# ESP32-P4 register map
Vendor: ESPRESSIF SYSTEMS (SHANGHAI) CO., LTD.; Series: ESP32 P-Series; File version: 3
CPU: RV32IMAFC r0p0, little endian, no MPU, FPU, 0 interrupt priority bits
Address unit: 32 bits
Registers are 32-bit, read-write, reset 0x0 unless marked. A register's access mark holds for its fields unless they carry their own. Offsets are from the block's base; [hi:lo] are bit positions; {n}, {i} and the like mark numbered series.

## I3C_MST_MEM — I3C_MST_MEM Peripheral
Base 0x500DA000
0x08 COMMAND_BUF_PORT
  [31:0] REG_COMMAND — Contains a Command Descriptor structure that depends on the requested transfer type. Command Descriptor structure is used to schedule the transfers to devices on I3C bus.
0x0C RESPONSE_BUF_PORT ro
  [31:0] RESPONSE — The Response Buffer can be read through this register. The response status for each Command is written into the Response Buffer by the controller if ROC (Response On Completion) bit is set or if transfer error has occurred. The response buffer can be read through this register.
0x10 RX_DATA_PORT ro
  [31:0] RX_DATA_PORT — Receive Data Port. Receive data is mapped to the Rx-data buffer and receive data is always packed in 4-byte aligned data words. If the length of data transfer is not aligned to 4-bytes boundary, then there will be extra(unused) bytes(the additional data bytes have to be ignored) at the end of the transferred data. The valid data must be identified using the DATA_LENGTH filed in the Response Descriptor.
0x14 TX_DATA_PORT
  [31:0] REG_TX_DATA_PORT — Transmit Data Port. Transmit data is mapped to the Tx-data buffer and transmit data is always packed in 4-byte aligned data words. If the length of data transfer is not aligned to 4-bytes boundary, then there will be extra(unused) bytes(the additional data bytes have to be ignored) at the end of the transferred data. The valid data must be identified using the DATA_LENGTH filed in the Response Descriptor.
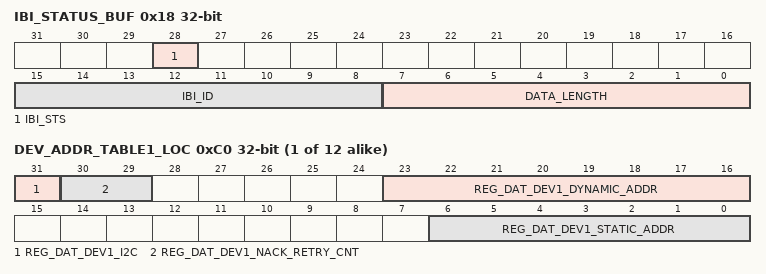
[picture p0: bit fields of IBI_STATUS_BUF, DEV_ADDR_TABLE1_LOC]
0x18 IBI_STATUS_BUF ro — In-Band Interrupt Buffer Status/Data Register. When receiving an IBI, IBI_PORT is used to both: Read the IBI Status Read the IBI Data(which is raw/opaque data)
  [28] IBI_STS — IBI received data/status. IBI Data register is mapped to the IBI Buffer. The IBI Data is always packed in4-byte aligned and put to the IBI Buffer. This register When read from, reads the data from the IBI buffer. IBI Status register when read from, returns the data from the IBI Buffer and indicates how the controller responded to incoming IBI(SIR, MR and HJ).
  [15:8] IBI_ID — IBI Identifier. The byte received after START which includes the address the R/W bit: Device address and R/W bit in case of Slave Interrupt or Master Request.
  [7:0] DATA_LENGTH — This field represents the length of data received along with IBI, in bytes.
0x40 IBI_DATA_BUF ro
  [31:0] IBI_DATA
{0xBC+4i} DEV_ADDR_TABLE{i}_LOC (i=1..12)
  [31] REG_DAT_DEV{i}_I2C — Legacy I2C device or not. This bit should be set to 1 if the device is a legacy I2C device.
  [30:29] REG_DAT_DEV{i}_NACK_RETRY_CNT — This field is used to set the Device NACK Retry count for the particular device. If the Device NACK's for the device address, the controller automatically retries the same device until this count expires. If the Slave does not ACK for the mentioned number of retries, then controller generates an error response and move to the Halt state.
  [23:16] REG_DAT_DEV{i}_DYNAMIC_ADDR — Device Dynamic Address with parity, The MSB,bit[23], should be programmed with parity of dynamic address.
  [6:0] REG_DAT_DEV{i}_STATIC_ADDR
{0xF0+0x10*i} DEV_CHAR_TABLE{i}_LOC1 ro (i=1..12)
  [31:0] DCT_DEV{i}_LOC1
{0xF4+0x10*i} DEV_CHAR_TABLE{i}_LOC2 ro (i=1..12)
  [31:0] DCT_DEV{i}_LOC2
{0xF8+0x10*i} DEV_CHAR_TABLE{i}_LOC3 ro (i=1..12)
  [31:0] DCT_DEV{i}_LOC3
{0xFC+0x10*i} DEV_CHAR_TABLE{i}_LOC4 ro (i=1..12)
  [31:0] DCT_DEV{i}_LOC4

## AXI_ICM — AXI_ICM Peripheral
Base 0x500A4000
0x00 VERID_FILEDS ro reset 0x3430342A
  [31:0] ICM_REG_VERID
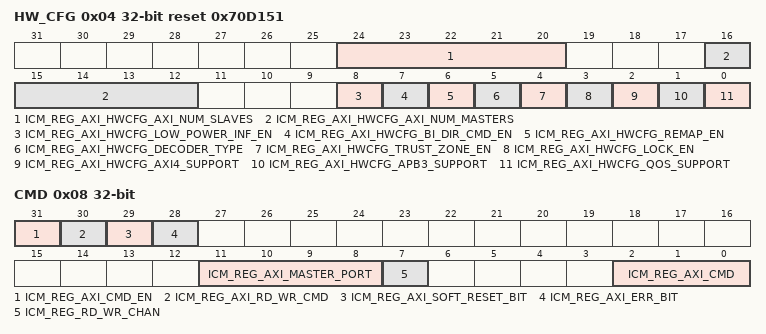
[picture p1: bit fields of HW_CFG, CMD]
0x04 HW_CFG ro reset 0x70D151
  [24:20] ICM_REG_AXI_HWCFG_AXI_NUM_SLAVES, [16:12] ICM_REG_AXI_HWCFG_AXI_NUM_MASTERS, [8] ICM_REG_AXI_HWCFG_LOW_POWER_INF_EN, [7] ICM_REG_AXI_HWCFG_BI_DIR_CMD_EN, [6] ICM_REG_AXI_HWCFG_REMAP_EN, [5] ICM_REG_AXI_HWCFG_DECODER_TYPE, [4] ICM_REG_AXI_HWCFG_TRUST_ZONE_EN, [3] ICM_REG_AXI_HWCFG_LOCK_EN, [2] ICM_REG_AXI_HWCFG_AXI4_SUPPORT, [1] ICM_REG_AXI_HWCFG_APB3_SUPPORT, [0] ICM_REG_AXI_HWCFG_QOS_SUPPORT
0x08 CMD access per field
  [31] ICM_REG_AXI_CMD_EN rw, [30] ICM_REG_AXI_RD_WR_CMD rw, [29] ICM_REG_AXI_SOFT_RESET_BIT rw, [28] ICM_REG_AXI_ERR_BIT ro, [11:8] ICM_REG_AXI_MASTER_PORT rw, [7] ICM_REG_RD_WR_CHAN rw, [2:0] ICM_REG_AXI_CMD rw
0x0C DATA
  [31:0] ICM_REG_DATA
